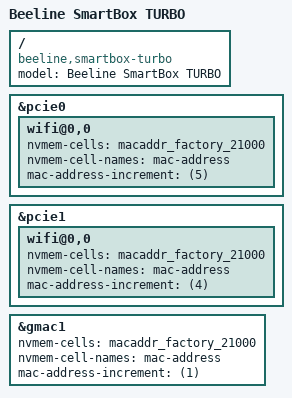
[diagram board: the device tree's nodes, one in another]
// SPDX-License-Identifier: GPL-2.0-or-later OR MIT

#include "mt7621_sercomm_dxx_nand_256m.dtsi"

/ {
	compatible = "beeline,smartbox-turbo", "mediatek,mt7621-soc";
	model = "Beeline SmartBox TURBO";
};

&pcie0 {
	wifi@0,0 {
		nvmem-cells = <&macaddr_factory_21000>;
		nvmem-cell-names = "mac-address";
		mac-address-increment = <(5)>;
	};
};

&pcie1 {
	wifi@0,0 {
		nvmem-cells = <&macaddr_factory_21000>;
		nvmem-cell-names = "mac-address";
		mac-address-increment = <(4)>;
	};
};

&gmac1 {
	nvmem-cells = <&macaddr_factory_21000>;
	nvmem-cell-names = "mac-address";
	mac-address-increment = <(1)>;
};
